AUTOSAR XML (schema 00046)
package /MICROSAR/Dcm_swc
  4 x mode declaration group, all with category=EXPLICIT_ORDER:
    DcmControlDtcSetting: initial-mode=ENABLEDTCSETTING, on-transition-value=2
      mode ENABLEDTCSETTING: value=0
      mode DISABLEDTCSETTING: value=1
    DcmEcuReset: initial-mode=NONE, on-transition-value=7
      7 x mode:
        NONE: value=0
        HARD: value=1
        KEYONOFF: value=2
        SOFT: value=3
        JUMPTOBOOTLOADER: value=4
        JUMPTOSYSSUPPLIERBOOTLOADER: value=5
        EXECUTE: value=6
    DcmDiagnosticSessionControl: initial-mode=DEFAULT_SESSION, on-transition-value=255
      mode DEFAULT_SESSION: value=1
      mode PROGRAMMING_SESSION: value=2
      mode EXTENDED_SESSION: value=3
    DcmCommunicationControl: initial-mode=DCM_ENABLE_RX_TX_NORM, on-transition-value=12
      12 x mode:
        DCM_ENABLE_RX_TX_NORM: value=0
        DCM_ENABLE_RX_DISABLE_TX_NORM: value=1
        DCM_DISABLE_RX_ENABLE_TX_NORM: value=2
        DCM_DISABLE_RX_TX_NORMAL: value=3
        DCM_ENABLE_RX_TX_NM: value=4
        DCM_ENABLE_RX_DISABLE_TX_NM: value=5
        DCM_DISABLE_RX_ENABLE_TX_NM: value=6
        DCM_DISABLE_RX_TX_NM: value=7
        DCM_ENABLE_RX_TX_NORM_NM: value=8
        DCM_ENABLE_RX_DISABLE_TX_NORM_NM: value=9
        DCM_DISABLE_RX_ENABLE_TX_NORM_NM: value=10
        DCM_DISABLE_RX_TX_NORM_NM: value=11
  data type mapping set DcmMappingSet  # Contains mapping for ModeDeclarationGroups which are provided by Dcm.
    mode-request-type-maps:
      implementation-data-type=Dcm_ControlDtcSettingType, mode-group=DcmControlDtcSetting
      implementation-data-type=Dcm_EcuResetType, mode-group=DcmEcuReset
      implementation-data-type=Dcm_DiagnosticSessionControlType, mode-group=DcmDiagnosticSessionControl
      implementation-data-type=Dcm_CommunicationModeType, mode-group=DcmCommunicationControl
package /MICROSAR/Dcm_swc/DataTypes
  11 x impl type:
    Dcm_ConfirmationStatusType: compu {0=DCM_RES_POS_OK, 1=DCM_RES_POS_NOT_OK, 2=DCM_RES_NEG_OK, 3=DCM_RES_NEG_NOT_OK}, range raw 0..3, implementation-data-type=uint8
    Dcm_OpStatusType: compu {0=DCM_INITIAL, 1=DCM_PENDING, 2=DCM_CANCEL, 3=DCM_FORCE_RCRRP_OK, 64=DCM_FORCE_RCRRP_NOT_OK}, range raw 0..64, implementation-data-type=uint8
    Dcm_NegativeResponseCodeType:
      compu {0=DCM_E_POSITIVERESPONSE, 16=DCM_E_GENERALREJECT, 17=DCM_E_SERVICENOTSUPPORTED, 18=DCM_E_SUBFUNCTIONNOTSUPPORTED, 19=DCM_E_INCORRECTMESSAGELENGTHORINVALIDFORMAT, 20=DCM_E_RESPONSETOOLONG, 33=DCM_E_BUSYREPEATREQUEST, 34=DCM_E_CONDITIONSNOTCORRECT, 36=DCM_E_REQUESTSEQUENCEERROR, 37=DCM_E_NORESPONSEFROMSUBNETCOMPONENT, 38=DCM_E_FAILUREPREVENTSEXECUTIONOFREQUESTEDACTION, 49=DCM_E_REQUESTOUTOFRANGE, 51=DCM_E_SECURITYACCESSDENIED, 53=DCM_E_INVALIDKEY, 54=DCM_E_EXCEEDNUMBEROFATTEMPTS, 55=DCM_E_REQUIREDTIMEDELAYNOTEXPIRED, 112=DCM_E_UPLOADDOWNLOADNOTACCEPTED, 113=DCM_E_TRANSFERDATASUSPENDED, 114=DCM_E_GENERALPROGRAMMINGFAILURE, 115=DCM_E_WRONGBLOCKSEQUENCECOUNTER, 120=DCM_E_REQUESTCORRECTLYRECEIVEDRESPONSEPENDING, 126=DCM_E_SUBFUNCTIONNOTSUPPORTEDINACTIVESESSION, 127=DCM_E_SERVICENOTSUPPORTEDINACTIVESESSION, 129=DCM_E_RPMTOOHIGH, 130=DCM_E_RPMTOOLOW, 131=DCM_E_ENGINEISRUNNING, 132=DCM_E_ENGINEISNOTRUNNING, 133=DCM_E_ENGINERUNTIMETOOLOW, 134=DCM_E_TEMPERATURETOOHIGH, 135=DCM_E_TEMPERATURETOOLOW, 136=DCM_E_VEHICLESPEEDTOOHIGH, 137=DCM_E_VEHICLESPEEDTOOLOW, 138=DCM_E_THROTTLE_PEDALTOOHIGH, 139=DCM_E_THROTTLE_PEDALTOOLOW, 140=DCM_E_TRANSMISSIONRANGENOTINNEUTRAL, 141=DCM_E_TRANSMISSIONRANGENOTINGEAR, 143=DCM_E_BRAKESWITCH_NOTCLOSED, 144=DCM_E_SHIFTERLEVERNOTINPARK, 145=DCM_E_TORQUECONVERTERCLUTCHLOCKED, 146=DCM_E_VOLTAGETOOHIGH, 147=DCM_E_VOLTAGETOOLOW, 240..249=DCM_E_VMSCNC_0..DCM_E_VMSCNC_9, 250=DCM_E_VMSCNC_A, 251=DCM_E_VMSCNC_B, 252=DCM_E_VMSCNC_C, 253=DCM_E_VMSCNC_D, 254=DCM_E_VMSCNC_E}
      range raw 0..254
      implementation-data-type=uint8
    Dcm_ProtocolType: compu {0=DCM_OBD_ON_CAN, 1=DCM_OBD_ON_FLEXRAY, 2=DCM_OBD_ON_IP, 3=DCM_UDS_ON_CAN, 4=DCM_UDS_ON_FLEXRAY, 5=DCM_UDS_ON_IP, 12=DCM_NO_ACTIVE_PROTOCOL, 240..254=DCM_SUPPLIER_1..DCM_SUPPLIER_15}, range raw 0..254, implementation-data-type=uint8
    Dcm_RequestKindType: compu {0=DCM_REQ_KIND_NONE, 1=DCM_REQ_KIND_EXTERNAL, 2=DCM_REQ_KIND_ROE}, range raw 0..2, implementation-data-type=uint8
    Dcm_SesCtrlType: compu {1=DCM_DEFAULT_SESSION, 2=DCM_PROGRAMMING_SESSION, 3=DCM_EXTENDED_DIAGNOSTIC_SESSION}, range raw 0..3, implementation-data-type=uint8
    Dcm_ControlDtcSettingType: compu {0=DCM_ENUM_ENABLEDTCSETTING, 1=DCM_ENUM_DISABLEDTCSETTING}, range raw 0..255, implementation-data-type=uint8
    Dcm_EcuResetType: compu {0=DCM_ENUM_NONE, 1=DCM_ENUM_HARD, 2=DCM_ENUM_KEYONOFF, 3=DCM_ENUM_SOFT, 4=DCM_ENUM_JUMPTOBOOTLOADER, 5=DCM_ENUM_JUMPTOSYSSUPPLIERBOOTLOADER, 6=DCM_ENUM_EXECUTE}, range raw 0..255, implementation-data-type=uint8
    Dcm_DiagnosticSessionControlType: compu {1=DCM_ENUM_DEFAULT_SESSION, 2=DCM_ENUM_PROGRAMMING_SESSION, 3=DCM_ENUM_EXTENDED_SESSION}, range raw 0..255, implementation-data-type=uint8
    Dcm_CommunicationModeType:
      compu {0=DCM_ENABLE_RX_TX_NORM, 1=DCM_ENABLE_RX_DISABLE_TX_NORM, 2=DCM_DISABLE_RX_ENABLE_TX_NORM, 3=DCM_DISABLE_RX_TX_NORMAL, 4=DCM_ENABLE_RX_TX_NM, 5=DCM_ENABLE_RX_DISABLE_TX_NM, 6=DCM_DISABLE_RX_ENABLE_TX_NM, 7=DCM_DISABLE_RX_TX_NM, 8=DCM_ENABLE_RX_TX_NORM_NM, 9=DCM_ENABLE_RX_DISABLE_TX_NORM_NM, 10=DCM_DISABLE_RX_ENABLE_TX_NORM_NM, 11=DCM_DISABLE_RX_TX_NORM_NM}
      range raw 0..255
      implementation-data-type=uint8
    Dcm_Data1ByteType: category=ARRAY, sw-calibration-access=READ-ONLY
      element Dcm_Data1ByteTypeElement: array-size=1, array-size-semantics=FIXED-SIZE, implementation-data-type=uint8
package /MICROSAR/Dcm_swc/Interfaces
  4 x mode switch interface, all with is-service=true, service-kind=DIAGNOSTIC-COMMUNICATION-MANAGER:
    DcmControlDtcSetting
      mode group DcmControlDtcSetting: type=DcmControlDtcSetting
    DcmEcuReset
      mode group DcmEcuReset: type=DcmEcuReset
    DcmDiagnosticSessionControl
      mode group DcmDiagnosticSessionControl: type=DcmDiagnosticSessionControl
    DcmCommunicationControl_ComMConf_ComMChannel_CN_DBCNetWork_9ed72b09
      mode group DcmCommunicationControl_ComMConf_ComMChannel_CN_DBCNetWork_9ed72b09: type=DcmCommunicationControl
  client server interface DCMServices: is-service=true, service-kind=DIAGNOSTIC-COMMUNICATION-MANAGER
    5 x operation:
      GetActiveProtocol: possible-error=E_OK
        arg ActiveProtocol: type=Dcm_ProtocolType, direction=OUT
      GetSesCtrlType: possible-error=E_OK
        arg SesCtrlType: type=Dcm_SesCtrlType, direction=OUT
      ResetToDefaultSession: possible-error=E_OK
      SetActiveDiagnostic: possible-error=E_OK
        arg active: type=boolean, direction=IN
      GetRequestKind: possible-error=DCMServices/E_NOT_OK
        arg TesterSourceAddress: type=uint16, direction=IN
        arg RequestKind: type=Dcm_RequestKindType, direction=OUT
    error E_OK: error-code=0
    error E_NOT_OK: error-code=1
  client server interface RoutineServices_ECU_Check: is-service=true, service-kind=DIAGNOSTIC-COMMUNICATION-MANAGER
    operation Start: possible-error=[RoutineServices_ECU_Check/E_NOT_OK, RoutineServices_ECU_Check/DCM_E_PENDING, DCM_E_FORCE_RCRRP]
      4 x arg:
        In_Start_ECU_Check: type=uint8, direction=IN
        OpStatus: type=Dcm_OpStatusType, direction=IN
        Out_ECU_Check_is_in_progress: type=uint8, direction=OUT
        ErrorCode: type=Dcm_NegativeResponseCodeType, direction=OUT
    operation RequestResults: possible-error=[RoutineServices_ECU_Check/E_NOT_OK, RoutineServices_ECU_Check/DCM_E_PENDING, DCM_E_FORCE_RCRRP]
      arg OpStatus: type=Dcm_OpStatusType, direction=IN
      arg Out_ECU_Check_status: type=uint8, direction=OUT
      arg ErrorCode: type=Dcm_NegativeResponseCodeType, direction=OUT
    error E_NOT_OK: error-code=1
    error DCM_E_PENDING: error-code=10
    error DCM_E_FORCE_RCRRP: error-code=12
  client server interface DataServices_Braking_Brake_Pedal: is-service=true, service-kind=DIAGNOSTIC-COMMUNICATION-MANAGER
    operation ReadData: possible-error=[DataServices_Braking_Brake_Pedal/E_NOT_OK, DataServices_Braking_Brake_Pedal/DCM_E_PENDING]
      arg OpStatus: type=Dcm_OpStatusType, direction=IN
      arg Data: type=Dcm_Data1ByteType, direction=OUT
    operation ConditionCheckRead: possible-error=[DataServices_Braking_Brake_Pedal/E_NOT_OK, DataServices_Braking_Brake_Pedal/DCM_E_PENDING]
      arg OpStatus: type=Dcm_OpStatusType, direction=IN
      arg ErrorCode: type=Dcm_NegativeResponseCodeType, direction=OUT
    error E_NOT_OK: error-code=1
    error DCM_E_PENDING: error-code=10
package /MICROSAR/Dcm_swc/ComponentTypes
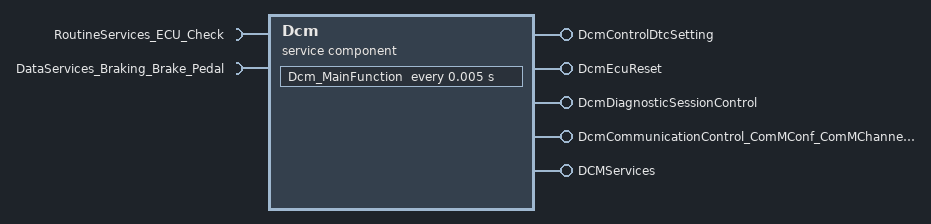
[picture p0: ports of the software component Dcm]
  service sw component type Dcm: category=SERVICE_COMPONENT
    5 x provide port:
      DcmControlDtcSetting: provided-interface=DcmControlDtcSetting
      DcmEcuReset: mode-switch-sender-com-spec{mode-group=DcmEcuReset, mode-switched-ack=timeout=0}, provided-interface=DcmEcuReset
      DcmDiagnosticSessionControl: provided-interface=DcmDiagnosticSessionControl
      DcmCommunicationControl_ComMConf_ComMChannel_CN_DBCNetWork_9ed72b09: provided-interface=DcmCommunicationControl_ComMConf_ComMChannel_CN_DBCNetWork_9ed72b09
      DCMServices: provided-interface=DCMServices
    require port RoutineServices_ECU_Check: required-interface=RoutineServices_ECU_Check
    require port DataServices_Braking_Brake_Pedal: required-interface=DataServices_Braking_Brake_Pedal
    behavior DcmInternalBehavior: data-type-mapping=DcmMappingSet, handle-termination-and-restart=NO-SUPPORT, included-data-type-set=data-type=[Dcm_ConfirmationStatusType, Dcm_OpStatusType, Dcm_NegativeResponseCodeType, Dcm_ProtocolType, Dcm_RequestKindType, Dcm_SesCtrlType, Dcm_ControlDtcSettingType, Dcm_EcuResetType, Dcm_DiagnosticSessionControlType, Dcm_CommunicationModeType]
      timing event Timer_Dcm_MainFunction: start-on-event=Dcm_MainFunction, period=0.005
      5 x operation invoked event:
        OpEventGetActiveProtocol_GetActiveProtocol_DCMServices: start-on-event=GetActiveProtocol, operation=DCMServices.GetActiveProtocol
        OpEventGetSesCtrlType_GetSesCtrlType_DCMServices: start-on-event=GetSesCtrlType, operation=DCMServices.GetSesCtrlType
        OpEventResetToDefaultSession_ResetToDefaultSession_DCMServices: start-on-event=ResetToDefaultSession, operation=DCMServices.ResetToDefaultSession
        OpEventSetActiveDiagnostic_SetActiveDiagnostic_DCMServices: start-on-event=SetActiveDiagnostic, operation=DCMServices.SetActiveDiagnostic
        OpEventGetRequestKind_GetRequestKind_DCMServices: start-on-event=GetRequestKind, operation=DCMServices.GetRequestKind
      port-api-options:
        enable-take-address=true, indirect-api=false, port=DcmControlDtcSetting
        enable-take-address=true, indirect-api=false, port=DcmEcuReset
        enable-take-address=true, indirect-api=false, port=DcmDiagnosticSessionControl
        enable-take-address=true, indirect-api=false, port=DcmCommunicationControl_ComMConf_ComMChannel_CN_DBCNetWork_9ed72b09
        enable-take-address=true, indirect-api=false, port=DCMServices
        enable-take-address=true, indirect-api=false, port=RoutineServices_ECU_Check
        enable-take-address=true, indirect-api=false, port=DataServices_Braking_Brake_Pedal
      6 x runnable:
        Dcm_MainFunction
          4 x mode switch point:
            ModeSwitchPointDcm_MainFunction_DcmControlDtcSetting_DcmControlDtcSetting: mode-group=DcmControlDtcSetting.DcmControlDtcSetting
            ModeSwitchPointDcm_MainFunction_DcmEcuReset_DcmEcuReset: mode-group=DcmEcuReset.DcmEcuReset
            ModeSwitchPointDcm_MainFunction_DcmDiagnosticSessionControl_DcmDiagnosticSessionControl: mode-group=DcmDiagnosticSessionControl.DcmDiagnosticSessionControl
            ModeSwitchPointDcm_MainFunction_DcmCommunicationControl_ComMConf_ComMChannel_CN_DBCNetWork_9ed72b09_DcmCommunicationCon_f3e1d13d: mode-group=DcmCommunicationControl_ComMConf_ComMChannel_CN_DBCNetWork_9ed72b09.DcmCommunicationControl_ComMConf_ComMChannel_CN_DBCNetWork_9ed72b09
          4 x sync call, all with timeout=0:
            OpServerCallDcm_MainFunction_Start_RoutineServices_ECU_Check: operation=RoutineServices_ECU_Check.Start
            OpServerCallDcm_MainFunction_RequestResults_RoutineServices_ECU_Check: operation=RoutineServices_ECU_Check.RequestResults
            OpServerCallDcm_MainFunction_ReadData_DataServices_Braking_Brake_Pedal: operation=DataServices_Braking_Brake_Pedal.ReadData
            OpServerCallDcm_MainFunction_ConditionCheckRead_DataServices_Braking_Brake_Pedal: operation=DataServices_Braking_Brake_Pedal.ConditionCheckRead
        GetActiveProtocol: can-be-invoked-concurrently=true, symbol=Dcm_GetActiveProtocol
        GetSesCtrlType: can-be-invoked-concurrently=true, symbol=Dcm_GetSesCtrlType
        ResetToDefaultSession: can-be-invoked-concurrently=true, symbol=Dcm_ResetToDefaultSession
        SetActiveDiagnostic: can-be-invoked-concurrently=true, symbol=Dcm_SetActiveDiagnostic
        GetRequestKind: can-be-invoked-concurrently=true, symbol=Dcm_GetRequestKind
  swc implementation DcmImplementation: programming-language=C, behavior=DcmInternalBehavior
